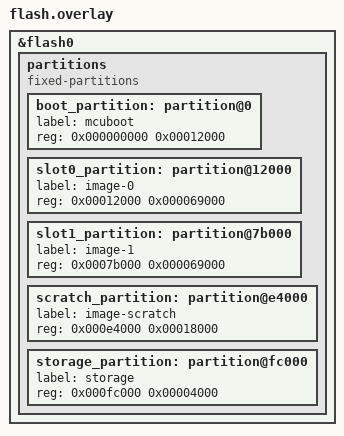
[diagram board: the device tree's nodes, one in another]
/* Configuration without nRF5 bootloader. */

/delete-node/ &boot_partition;
/delete-node/ &slot0_partition;
/delete-node/ &slot1_partition;
/delete-node/ &scratch_partition;
/delete-node/ &storage_partition;

&flash0 {
	partitions {
		compatible = "fixed-partitions";
		#address-cells = <1>;
		#size-cells = <1>;

		boot_partition: partition@0 {
			label = "mcuboot";
			reg = <0x000000000 0x00012000>;
		};
		slot0_partition: partition@12000 {
			label = "image-0";
			reg = <0x00012000 0x000069000>;
		};
		slot1_partition: partition@7b000 {
			label = "image-1";
			reg = <0x0007b000 0x000069000>;
		};
		scratch_partition: partition@e4000 {
			label = "image-scratch";
			reg = <0x000e4000 0x00018000>;
		};
		storage_partition: partition@fc000 {
			label = "storage";
			reg = <0x000fc000 0x00004000>;
		};
	};
};
